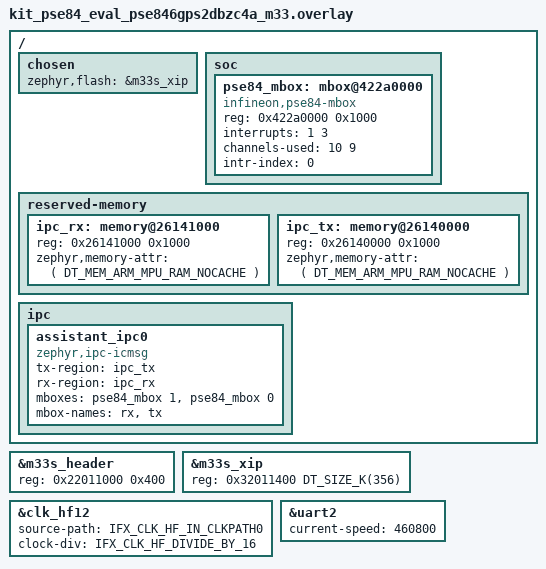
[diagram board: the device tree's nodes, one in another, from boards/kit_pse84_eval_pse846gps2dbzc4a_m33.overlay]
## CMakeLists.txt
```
# PSE84 Voice Assistant — M33 companion.
#
# This is the M33 image that replaces samples/basic/minimal in the
# kit_pse84_eval sysbuild companion slot. Its jobs today are:
#
#   1. Drive ifx_pse84_cm55_startup() via the SoC's soc_late_init_hook
#      (CONFIG_SOC_PSE84_M55_ENABLE=y + CONFIG_PSE84_MAIN_THREAD_DISABLED=n).
#   2. Set CLK_HF12 to a useful frequency for the MIPI-DSI D-PHY PLL.
#   3. Keep the M33 running after CM55 handoff so we can eventually
#      host the Bluetooth stack + ipc_service peer here.
#
# Phase 0b.7: skeleton only — main() just logs a heartbeat so we can
# verify the new image runs where samples/basic/minimal used to.
# Phase 4+: bring up CONFIG_BT + HCI UART + AIROC firmware download.

cmake_minimum_required(VERSION 3.20.0)

find_package(Zephyr REQUIRED HINTS $ENV{ZEPHYR_BASE})
project(pse84_assistant_m33)

target_sources(app PRIVATE src/main.c)
```

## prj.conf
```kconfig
# PSE84 Voice Assistant — M33 companion (silent + IPC tunnel).
#
# Console/SERIAL deliberately omitted. The M33 root-cause hardfault
# (BFAR=0x529A0000, see embedded/docs/pse84_m33_secure_uart_fault.md)
# only triggers on Secure-alias accesses. The mbox driver uses the
# NS alias (0x422A0000) per the M33 board overlay, so MBOX + IPC are
# safe even after cy_ppc_init flips PERI0 to NS.

CONFIG_GPIO=y
CONFIG_PINCTRL=y
CONFIG_CLOCK_CONTROL=y
CONFIG_MAIN_STACK_SIZE=4096

# IPC tunnel to M55 (silent — M33 has no console, so ep_recv stores
# bytes in shared SOCMEM rather than printing them).
CONFIG_MBOX=y
CONFIG_IPC_SERVICE=y
CONFIG_IPC_SERVICE_BACKEND_ICMSG=y
```

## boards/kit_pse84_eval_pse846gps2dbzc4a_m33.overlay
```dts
/*
 * PSE84 Voice Assistant — M33 companion board overlay.
 *
 * Mirrors sysbuild/enable_cm55.overlay from pse84_assistant: route
 * CLK_HF12 to CLKPATH0 (DPLL_LP0 = 400 MHz) divided by 16 to yield
 * 25 MHz — close enough to the external 24 MHz oscillator spec for
 * the MIPI-DSI D-PHY PLL reference on CLKPATH4.
 *
 * Without this override CLK_HF12 defaults to the CLKPATH4 source that
 * is not running, so HF12 = 0 Hz and Cy_MIPI_DSI_Dphy_Enable() spins
 * forever in its unbounded PHY_LOCK polling loop.
 */

#include <zephyr/dt-bindings/clock/ifx_clock_source_common.h>
#include <zephyr/dt-bindings/memory-attr/memory-attr-arm.h>

/*
 * Phase 0c — link M33 Secure into RRAM so extended-boot can actually
 * load + run what `west flash` wrote. The default kit partition map
 * places m33s_xip at 0x18100400 (internal-flash Secure XIP alias),
 * but the OEM policy's `oem_app_address = 0x32011000` points into
 * RRAM (Secure alias 0x3xxx_xxxx / NS alias 0x2xxx_xxxx, openocd
 * bank #0 `cat1d.cm33.main_ns`). Override the partitions so the
 * linker emits an image that matches where the boot ROM + openocd
 * flash actually put it. Matches pse84_i2c_test's overlay exactly.
 */
&m33s_header { reg = <0x22011000 0x400>; };
&m33s_xip { reg = <0x32011400 DT_SIZE_K(356)>; };
/ { chosen { zephyr,flash = &m33s_xip; }; };

&clk_hf12 {
	source-path = <IFX_CLK_HF_IN_CLKPATH0>;
	clock-div = <IFX_CLK_HF_DIVIDE_BY_16>;
	status = "okay";
};

/*
 * M55 overrides uart2 to 460800 baud for the Phase 2 PCM hex dump.
 * Both cores share uart2 as console (hardware contention: whichever
 * core writes first wins; occasional interleaved bytes are expected).
 * Match the baud here so M33 printk output is at least decodable by
 * the host serial monitor. Longer-term fix: route M33 console to a
 * different SCB or forward M33 logs to M55 via ipc_service.
 */
&uart2 {
	current-speed = <460800>;
};

/*
 * Phase 0b.8: M33 side of the assistant ipc_service endpoint.
 *
 * Mirrors pse84_assistant/boards/.../m55.overlay's mbox + ipc nodes
 * but with TX/RX channels swapped so the icmsg ring matches:
 *   M55 TX (ch9) → M33 RX (ch9)
 *   M55 RX (ch10) → M33 TX (ch10)
 *
 * NVIC IRQ 1 = m33syscpuss_interrupts_ipc_dpslp_0_IRQn (DeepSleep
 * table) per modules/hal/infineon/zephyr-ifx-cycfg/.../device_headers/
 * cy_device_headers_ns.h. intr-index=0 mirrors the M55 side so each
 * CPU listens on its own per-CPU intr struct 0.
 *
 * `reg` is informational only — the driver dispatches via Cy_IPC_Drv_*
 * which knows the correct per-CPU MMIO alias (0x422a0000 NS / secure
 * alias for M33 vs 0x441d0000 for M55).
 *
 * Shared-memory regions are pinned at the same physical addresses as
 * the M55 side; both cores see the same SOCMEM, so labels swap roles
 * (M33's RX = the buffer M55 writes to = ipc_tx, and vice versa).
 */
/ {
	soc {
		pse84_mbox: mbox@422a0000 {
			compatible = "infineon,pse84-mbox";
			reg = <0x422a0000 0x1000>;
			interrupts = <1 3>;
			channels-used = <10 9>;
			intr-index = <0>;
			#mbox-cells = <1>;
			status = "okay";
		};
	};

	reserved-memory {
		#address-cells = <1>;
		#size-cells = <1>;

		/* ICMSG shared rings in SOCMEM gap (see M55 overlay for
		 * rationale). M33's RX is the buffer M55 writes to =
		 * M55's ipc_tx @ 0x26141000. M33's TX is the buffer
		 * M55 reads from = M55's ipc_rx @ 0x26140000. Labels swap
		 * roles between cores; addresses are fixed. */
		ipc_rx: memory@26141000 {
			reg = <0x26141000 0x1000>;
			zephyr,memory-attr = <( DT_MEM_ARM_MPU_RAM_NOCACHE )>;
		};
		ipc_tx: memory@26140000 {
			reg = <0x26140000 0x1000>;
			zephyr,memory-attr = <( DT_MEM_ARM_MPU_RAM_NOCACHE )>;
		};
	};

	ipc {
		assistant_ipc0: assistant_ipc0 {
			compatible = "zephyr,ipc-icmsg";
			tx-region = <&ipc_tx>;
			rx-region = <&ipc_rx>;
			mboxes = <&pse84_mbox 1>, <&pse84_mbox 0>;
			mbox-names = "rx", "tx";
			status = "okay";
		};
	};
};
```

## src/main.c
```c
/*
 * PSE84 Voice Assistant — M33 companion (silent + IPC).
 *
 * Layout (SRAM markers — read via openocd `mdw`):
 *   0x34039f00  general state word: 0xBEEF<counter>
 *                 counter ticks fast in main loop
 *   0x34039f04  IPC state word: 0xC0FFE<state>
 *                 0=before init, 1=device-not-ready, 2=open-failed,
 *                 3=register-failed, 4=registered, 5=bound,
 *                 6=first-rx-received
 *   0x34039f08  IPC rx counter
 *   0x34039f0c  IPC last rx-byte size
 *   0x34039f10  scratch buffer (256 B) for last rx payload
 *
 * No SERIAL → no console_out → no SCB2 fault. mbox driver uses NS
 * alias 0x422A0000 which Cortex-M33 Secure can still access after
 * cy_ppc_init flips PERI0 to NS.
 *
 * M33-Secure also needs Cy_IPC_Pipe_Config + Cy_IPC_Sema_Init at
 * main() entry — M55 gets this via soc_early_init_hook on its side,
 * but the CM33-Secure SOC code path has no equivalent and Zephyr
 * ipc_service icmsg backend asserts z_spin_lock_valid without it.
 */
#include <zephyr/kernel.h>
#include <zephyr/device.h>
#include <zephyr/ipc/ipc_service.h>

#include "cy_ipc_pipe.h"
#include "cy_ipc_sema.h"

#define DIAG_MARKER_ADDR  0x34039f00U
#define IPC_STATE_ADDR    0x34039f04U
#define IPC_RX_COUNT_ADDR 0x34039f08U
#define IPC_LAST_LEN_ADDR 0x34039f0cU
#define IPC_SCRATCH_ADDR  0x34039f10U
#define IPC_SCRATCH_SIZE  256U

static volatile uint32_t *const diag_marker  = (volatile uint32_t *)DIAG_MARKER_ADDR;
static volatile uint32_t *const ipc_state    = (volatile uint32_t *)IPC_STATE_ADDR;
static volatile uint32_t *const ipc_rx_count = (volatile uint32_t *)IPC_RX_COUNT_ADDR;
static volatile uint32_t *const ipc_last_len = (volatile uint32_t *)IPC_LAST_LEN_ADDR;
static volatile uint8_t  *const ipc_scratch  = (volatile uint8_t  *)IPC_SCRATCH_ADDR;

#define IPC_STATE(s) (0xC0FFE000U | (s))

#define CY_IPC_MAX_ENDPOINTS (8UL)
static cy_stc_ipc_pipe_ep_t systemIpcPipeEpArray[CY_IPC_MAX_ENDPOINTS];

static void ep_recv(const void *data, size_t len, void *priv)
{
	ARG_UNUSED(priv);
	(*ipc_rx_count)++;
	*ipc_last_len = (uint32_t)len;
	if (*ipc_state < IPC_STATE(6)) {
		*ipc_state = IPC_STATE(6);
	}
	size_t copy = (len < IPC_SCRATCH_SIZE) ? len : IPC_SCRATCH_SIZE;
	const uint8_t *p = data;
	for (size_t i = 0; i < copy; i++) {
		ipc_scratch[i] = p[i];
	}
}

static void ep_bound(void *priv)
{
	ARG_UNUSED(priv);
	*ipc_state = IPC_STATE(5);
}

int main(void)
{
	*diag_marker  = 0xBEEF0001U;
	*ipc_state    = IPC_STATE(0);
	*ipc_rx_count = 0U;
	*ipc_last_len = 0U;

	Cy_IPC_Pipe_Config(systemIpcPipeEpArray);
	(void)Cy_IPC_Sema_Init(IPC0_SEMA_CH_NUM, 0UL, NULL);

	const struct device *ipc_dev =
		DEVICE_DT_GET(DT_NODELABEL(assistant_ipc0));
	static struct ipc_ept ep;
	static const struct ipc_ept_cfg cfg = {
		.name = "assistant",
		.cb = {
			.bound = ep_bound,
			.received = ep_recv,
		},
	};

	if (!device_is_ready(ipc_dev)) {
		*ipc_state = IPC_STATE(1);
	} else if (ipc_service_open_instance(ipc_dev) < 0) {
		*ipc_state = IPC_STATE(2);
	} else if (ipc_service_register_endpoint(ipc_dev, &ep, &cfg) < 0) {
		*ipc_state = IPC_STATE(3);
	} else {
		*ipc_state = IPC_STATE(4);
	}

	volatile uint32_t counter = 0;
	while (1) {
		counter++;
		*diag_marker = 0xBEEF0000U | (counter & 0xFFFFU);
		/* k_yield (not k_sleep!) — yields CPU without queuing a
		 * timeout. icmsg work queue + ISR back-half can run here.
		 * k_sleep faults M33 in z_add_timeout assertion (the
		 * MCWDT/timer subsystem isn't fully sane on M33-Secure
		 * after PPC re-attribution). */
		k_yield();
	}
	return 0;
}
```
